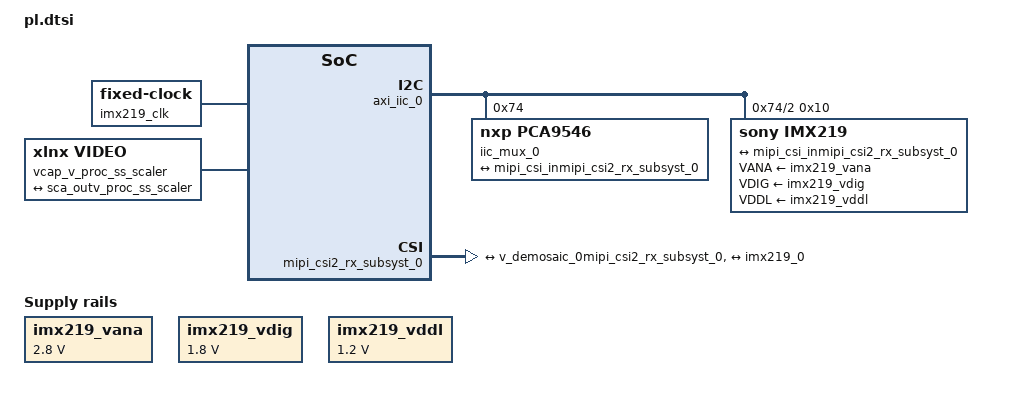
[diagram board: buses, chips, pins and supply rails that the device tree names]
/*
 * CAUTION: This file is automatically generated by Xilinx.
 * Version: XSCT 2022.1
 * Today is: Thu Jul 28 16:23:50 2022
 */


/dts-v1/;
/plugin/;
/ {
	fragment@0 {
		target = <&fpga_full>;
		overlay0: __overlay__ {
			#address-cells = <2>;
			#size-cells = <2>;
			firmware-name = "kv260_mipicsi2_simpleISP.bin";
			resets = <&zynqmp_reset 116>;
		};
	};
	fragment@1 {
		target = <&amba>;
		overlay1: __overlay__ {
			afi0: afi0 {
				compatible = "xlnx,afi-fpga";
				config-afi = < 0 0>, <1 0>, <2 0>, <3 0>, <4 0>, <5 0>, <6 0>, <7 0>, <8 0>, <9 0>, <10 0>, <11 0>, <12 0>, <13 0>, <14 0xa00>, <15 0x000>;
			};
			clocking0: clocking0 {
				#clock-cells = <0>;
				assigned-clock-rates = <99999001>;
				assigned-clocks = <&zynqmp_clk 71>;
				clock-output-names = "fabric_clk";
				clocks = <&zynqmp_clk 71>;
				compatible = "xlnx,fclk";
			};
			clocking1: clocking1 {
				#clock-cells = <0>;
				assigned-clock-rates = <99999001>;
				assigned-clocks = <&zynqmp_clk 72>;
				clock-output-names = "fabric_clk";
				clocks = <&zynqmp_clk 72>;
				compatible = "xlnx,fclk";
			};
		};
	};
	fragment@2 {
		target-path="/";
		overlay2: __overlay__ {
			imx219_vana: fixedregulator0 {
				compatible = "regulator-fixed";
				regulator-name = "imx219_vana";
				regulator-min-microvolt = <2800000>;
				regulator-max-microvolt = <2800000>;
			};
			imx219_vdig: fixedregulator1 {
				compatible = "regulator-fixed";
				regulator-name = "imx219_vdig";
				regulator-min-microvolt = <1800000>;
				regulator-max-microvolt = <1800000>;
			};
			imx219_vddl: fixedregulator2 {
				compatible = "regulator-fixed";
				regulator-name = "imx219_vddl";
				regulator-min-microvolt = <1200000>;
				regulator-max-microvolt = <1200000>;
			};
			imx219_clk:camera-clk {
				compatible = "fixed-clock";
				#clock-cells = <0>;
				clock-frequency = <24000000>;
			};
		};
	};
	fragment@3 {
		target = <&amba>;
		overlay3: __overlay__ {
			#address-cells = <2>;
			#size-cells = <2>;
			axi_iic_0: i2c@80030000 {
				#address-cells = <1>;
				#size-cells = <0>;
				clock-names = "s_axi_aclk";
				clocks = <&misc_clk_0>;
				compatible = "xlnx,axi-iic-2.1", "xlnx,xps-iic-2.00.a";
				interrupt-names = "iic2intc_irpt";
				interrupt-parent = <&gic>;
				interrupts = <0 104 4>;
				reg = <0x0 0x80030000 0x0 0x10000>;
				iic_mux_0: i2c_mux@74 { /* u18 */
					compatible = "nxp,pca9546";
					#address-cells = <1>;
					#size-cells = <0>;
					reg = <0x74>;
					isa0_i2c0: i2c@0 {
						reg = <0>;
					};
					isa1_i2c1: i2c@1 {
						reg = <1>;
					};
					rpi_i2c2: i2c@2 {
						#address-cells = <1>;
						#size-cells = <0>;
						reg = <2>;
						imx219: sensor@10 {
							compatible = "sony,imx219";
							reg = <0x10>;
							clocks = <&imx219_clk>;
							VANA-supply = <&imx219_vana>;   /* 2.8v */
							VDIG-supply = <&imx219_vdig>;   /* 1.8v */
							VDDL-supply = <&imx219_vddl>;   /* 1.2v */
							port {
								imx219_0: endpoint {
									remote-endpoint = <&mipi_csi_inmipi_csi2_rx_subsyst_0>;
									data-lanes = <1 2>;
									clock-noncontinuous;
									link-frequencies = /bits/ 64 <456000000>;
				   				};
							};
						};
					};
				/* Bus 4/4 are not connected */
				};
			};
			misc_clk_0: misc_clk_0 {
				#clock-cells = <0>;
				clock-frequency = <99999000>;
				compatible = "fixed-clock";
			};
			mipi_csi2_rx_subsyst_0: mipi_csi2_rx_subsystem@80002000 {
				clock-names = "lite_aclk", "dphy_clk_200M", "video_aclk";
				clocks = <&misc_clk_0>, <&misc_clk_1>, <&misc_clk_1>;
				compatible = "xlnx,mipi-csi2-rx-subsystem-5.0";
				interrupt-names = "csirxss_csi_irq";
				interrupt-parent = <&gic>;
				interrupts = <0 105 4>;
				reg = <0x0 0x80002000 0x0 0x2000>;
				xlnx,axis-tdata-width = <32>;
				xlnx,csi-pxl-format = <0x2b>;
				xlnx,en-active-lanes;
				xlnx,en-csi-v2-0;
				xlnx,en-vcx;
				xlnx,max-lanes = <2>;
				xlnx,ppc = <2>;
				xlnx,vc = <4>;
				xlnx,vfb;
				mipi_csi_portsmipi_csi2_rx_subsyst_0: ports {
					#address-cells = <1>;
					#size-cells = <0>;
					mipi_csi_port1mipi_csi2_rx_subsyst_0: port@1 {
						/* Fill cfa-pattern=rggb for raw data types, other fields video-format and video-width user needs to fill */
						reg = <1>;
						//xlnx,cfa-pattern = "rggb";
						//xlnx,video-format = <12>;
						xlnx,video-width = <10>;
						mipi_csirx_outmipi_csi2_rx_subsyst_0: endpoint {
							remote-endpoint = <&v_demosaic_0mipi_csi2_rx_subsyst_0>;
						};
					};
					mipi_csi_port0mipi_csi2_rx_subsyst_0: port@0 {
						/* Fill cfa-pattern=rggb for raw data types, other fields video-format,video-width user needs to fill */
						/* User need to add something like remote-endpoint=<&out> under the node csiss_in:endpoint */
						reg = <0>;
						//xlnx,cfa-pattern = "rggb";
						//xlnx,video-format = <12>;
						xlnx,video-width = <10>;
						mipi_csi_inmipi_csi2_rx_subsyst_0: endpoint {
                            remote-endpoint = <&imx219_0>;
							data-lanes = <1 2>;
						};
					};
				};
			};
			misc_clk_1: misc_clk_1 {
				#clock-cells = <0>;
				clock-frequency = <199998000>;
				compatible = "fixed-clock";
			};
			v_demosaic_0: v_demosaic@a0010000 {
				clock-names = "ap_clk";
				clocks = <&misc_clk_1>;
				compatible = "xlnx,v-demosaic-1.1", "xlnx,v-demosaic";
				interrupt-names = "interrupt";
				interrupt-parent = <&gic>;
				interrupts = <0 106 4>;
				reg = <0x0 0xa0010000 0x0 0x10000>;
				reset-gpios = <&gpio 78 1>;
				xlnx,max-height = <2160>;
				xlnx,max-width = <3840>;
				xlnx,s-axi-ctrl-addr-width = <0x6>;
				xlnx,s-axi-ctrl-data-width = <0x20>;
				demosaic_portsv_demosaic_0: ports {
					#address-cells = <1>;
					#size-cells = <0>;
					demosaic_port1v_demosaic_0: port@1 {
						/* For cfa-pattern=rggb user needs to fill as per BAYER format */
						reg = <1>;
						//xlnx,cfa-pattern = "rggb";
						//xlnx,video-format = <2>;
						xlnx,video-width = <10>;
						demo_outv_demosaic_0: endpoint {
							remote-endpoint = <&v_gamma_lut_0v_demosaic_0>;
						};
					};
					demosaic_port0v_demosaic_0: port@0 {
						/* For cfa-pattern=rggb user needs to fill as per BAYER format */
						reg = <0>;
						//xlnx,cfa-pattern = "rggb";
						xlnx,video-width = <10>;
						v_demosaic_0mipi_csi2_rx_subsyst_0: endpoint {
							remote-endpoint = <&mipi_csirx_outmipi_csi2_rx_subsyst_0>;
						};
					};
				};
			};
			v_frmbuf_wr_0: v_frmbuf_wr@a0020000 {
				#dma-cells = <1>;
				clock-names = "ap_clk";
				clocks = <&misc_clk_1>;
				compatible = "xlnx,v-frmbuf-wr-2.4", "xlnx,axi-frmbuf-wr-v2.2";
				interrupt-names = "interrupt";
				interrupt-parent = <&gic>;
				interrupts = <0 108 4>;
				reg = <0x0 0xa0020000 0x0 0x10000>;
				reset-gpios = <&gpio 82 1>;
				xlnx,dma-addr-width = <32>;
				xlnx,dma-align = <16>;
				xlnx,max-height = <2160>;
				xlnx,max-width = <3840>;
				xlnx,pixels-per-clock = <2>;
				xlnx,s-axi-ctrl-addr-width = <0x7>;
				xlnx,s-axi-ctrl-data-width = <0x20>;
				xlnx,vid-formats = "rgb888", "bgr888", "xbgr8888", "xrgb8888", "xbgr2101010", "vuy888", "xvuy8888", "nv12";
				xlnx,video-width = <10>;
			};
			v_gamma_lut_0: v_gamma_lut@a0030000 {
				clock-names = "ap_clk";
				clocks = <&misc_clk_1>;
				compatible = "xlnx,v-gamma-lut-1.1", "xlnx,v-gamma-lut";
				interrupt-names = "interrupt";
				interrupt-parent = <&gic>;
				interrupts = <0 107 4>;
				reg = <0x0 0xa0030000 0x0 0x10000>;
				reset-gpios = <&gpio 79 1>;
				xlnx,max-height = <2160>;
				xlnx,max-width = <3840>;
				xlnx,s-axi-ctrl-addr-width = <13>;
				xlnx,s-axi-ctrl-data-width = <32>;
				gamma_portsv_gamma_lut_0: ports {
					#address-cells = <1>;
					#size-cells = <0>;
					gamma_port1v_gamma_lut_0: port@1 {
						reg = <1>;
						xlnx,video-format = <2>;
						xlnx,video-width = <10>;
						gamma_outv_gamma_lut_0: endpoint {
							remote-endpoint = <&v_proc_ss_cscv_gamma_lut_0>;
						};
					};
					gamma_port0v_gamma_lut_0: port@0 {
						reg = <0>;
						xlnx,video-format = <2>;
						xlnx,video-width = <10>;
						v_gamma_lut_0v_demosaic_0: endpoint {
							remote-endpoint = <&demo_outv_demosaic_0>;
						};
					};
				};
			};
			v_proc_ss_csc: v_proc_ss_csc@a0040000 {
				clock-names = "aclk";
				clocks = <&misc_clk_1>;
				compatible = "xlnx,v-vpss-csc";
				reg = <0x0 0xa0040000 0x0 0x10000>;
				reset-gpios = <&gpio 80 1>;
				xlnx,colorspace-support = <1>;
				//xlnx,csc-enable-window = "true";
				xlnx,max-height = <2160>;
				xlnx,max-width = <3840>;
				//xlnx,num-video-components = <3>;
				xlnx,samples-per-clk = <2>;
				//xlnx,topology = <3>;
				xlnx,use-uram = <0>;
				xlnx,video-width = <10>;
				csc_portsv_proc_ss_csc: ports {
					#address-cells = <1>;
					#size-cells = <0>;
					csc_port1v_proc_ss_csc: port@1 {
						/* For xlnx,video-format user needs to fill as per their requirement */
						reg = <1>;
						xlnx,video-format = <3>;
						xlnx,video-width = <8>;
						csc_outv_proc_ss_csc: endpoint {
							remote-endpoint = <&v_proc_ss_scalerv_proc_ss_csc>;
						};
					};
					csc_port0v_proc_ss_csc: port@0 {
						/* For xlnx,video-format user needs to fill as per their requirement */
						reg = <0>;
						xlnx,video-format = <2>;
						xlnx,video-width = <8>;
						v_proc_ss_cscv_gamma_lut_0: endpoint {
							remote-endpoint = <&gamma_outv_gamma_lut_0>;
						};
					};
				};
			};
			v_proc_ss_scaler: v_proc_ss_scaler@a0080000 {
				clock-names = "aclk_axis", "aclk_ctrl";
				clocks = <&misc_clk_1>, <&misc_clk_1>;
				compatible = "xlnx,v-vpss-scaler-2.2";
				reg = <0x0 0xa0080000 0x0 0x40000>;
				reset-gpios = <&gpio 81 1>;
				xlnx,colorspace-support = <1>;
				xlnx,csc-enable-window = "true";
				xlnx,enable-csc = "false";
				xlnx,h-scaler-phases = <64>;
				xlnx,h-scaler-taps = <6>;
				xlnx,max-height = <2160>;
				xlnx,max-num-phases = <64>;
				xlnx,max-width = <3840>;
				xlnx,num-hori-taps = <6>;
				xlnx,num-vert-taps = <6>;
				xlnx,pix-per-clk = <2>;
				xlnx,samples-per-clk = <2>;
				xlnx,scaler-algorithm = <2>;
				xlnx,topology = <0>;
				xlnx,use-uram = <0>;
				xlnx,v-scaler-phases = <64>;
				xlnx,v-scaler-taps = <6>;
				xlnx,video-width = <10>;
				scaler_portsv_proc_ss_scaler: ports {
					#address-cells = <1>;
					#size-cells = <0>;
					scaler_port1v_proc_ss_scaler: port@1 {
						/* For xlnx,video-format user needs to fill as per their requirement */
						reg = <1>;
						xlnx,video-format = <3>;
						xlnx,video-width = <10>;
						sca_outv_proc_ss_scaler: endpoint {
							remote-endpoint = <&v_frmbuf_wr_0v_proc_ss_scaler>;
						};
					};
					scaler_port0v_proc_ss_scaler: port@0 {
						/* For xlnx,video-format user needs to fill as per their requirement */
						reg = <0>;
						xlnx,video-format = <3>;
						xlnx,video-width = <10>;
						v_proc_ss_scalerv_proc_ss_csc: endpoint {
							remote-endpoint = <&csc_outv_proc_ss_csc>;
						};
					};
				};
			};
			vcap_v_proc_ss_scaler {
				compatible = "xlnx,video";
				dma-names = "port0";
				dmas = <&v_frmbuf_wr_0 0>;
				vcap_portsv_proc_ss_scaler: ports {
					#address-cells = <1>;
					#size-cells = <0>;
					port@0 {
						reg = <0>;
						direction = "input";
						v_frmbuf_wr_0v_proc_ss_scaler: endpoint {
							remote-endpoint = <&sca_outv_proc_ss_scaler>;
						};
					};
				};
			};
		};
	};
};
